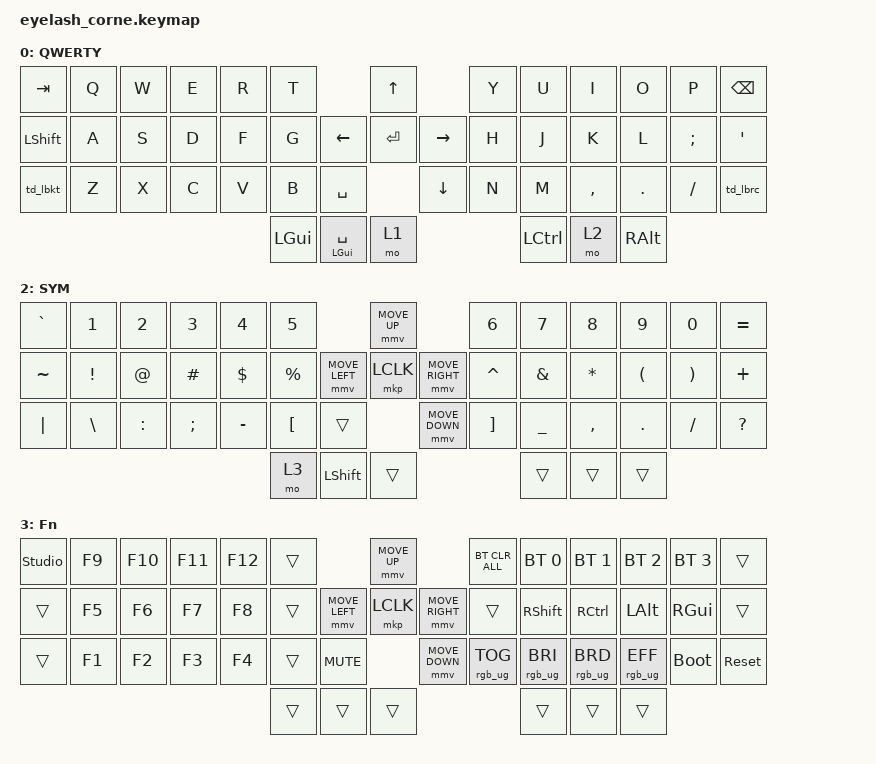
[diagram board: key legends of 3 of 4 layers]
#define ZMK_POINTING_DEFAULT_MOVE_VAL 1200  // 600
#define ZMK_POINTING_DEFAULT_SCRL_VAL 25   // 10

#include <input/processors.dtsi>
#include <zephyr/dt-bindings/input/input-event-codes.h>
#include <behaviors.dtsi>
#include <dt-bindings/zmk/bt.h>
#include <dt-bindings/zmk/keys.h>
#include <dt-bindings/zmk/outputs.h>
#include <dt-bindings/zmk/pointing.h>
#include <dt-bindings/zmk/rgb.h>

&mmv_input_listener { input-processors = <&zip_xy_scaler 2 1>; };

&msc_input_listener { input-processors = <&zip_scroll_scaler 2 1>; };

&msc {
    acceleration-exponent = <1>;
    time-to-max-speed-ms = <100>;
    delay-ms = <0>;
};

&mmv {
    time-to-max-speed-ms = <500>;
    acceleration-exponent = <1>;
    trigger-period-ms = <16>;
};

&soft_off { hold-time-ms = <2000>; };

/ {
    macros {
        lbkt_pair: lbkt_pair {
            compatible = "zmk,behavior-macro";
            #binding-cells = <0>;
            wait-ms = <0>;
            tap-ms = <10>;
            bindings = <&kp LBKT &kp RBKT &kp LEFT>;
        };

        lbrc_pair: lbrc_pair {
            compatible = "zmk,behavior-macro";
            #binding-cells = <0>;
            wait-ms = <0>;
            tap-ms = <10>;
            bindings = <&kp LBRC &kp RBRC &kp LEFT>;
        };
    };

    behaviors {
        td_lbkt: td_lbkt {
            compatible = "zmk,behavior-tap-dance";
            #binding-cells = <0>;
            tapping-term-ms = <200>;
            bindings = <&kp LBKT>, <&lbkt_pair>;
        };

        td_lbrc: td_lbrc {
            compatible = "zmk,behavior-tap-dance";
            #binding-cells = <0>;
            tapping-term-ms = <200>;
            bindings = <&kp LBRC>, <&lbrc_pair>;
        };

        gui_spc: gui_spc {
            compatible = "zmk,behavior-hold-tap";
            #binding-cells = <2>;
            flavor = "tap-preferred";
            tapping-term-ms = <200>;
            require-prior-idle-ms = <150>;
            bindings = <&kp>, <&kp>;
        };
    };

    rgb_encoder: rgb_encoder {
        compatible = "zmk,behavior-sensor-rotate";
        #sensor-binding-cells = <0>;
        bindings = <&rgb_ug RGB_BRI>, <&rgb_ug RGB_BRD>;
    };

    scroll_encoder: scroll_encoder {
        compatible = "zmk,behavior-sensor-rotate";
        #sensor-binding-cells = <0>;
        bindings = <&msc SCRL_DOWN>, <&msc SCRL_UP>;
        tap-ms = <100>;
    };

    combos {
        compatible = "zmk,combos";

        softoff {
            bindings = <&soft_off>;
            key-positions = <1 15 29>;
        };

        combo_esc {
            bindings = <&kp ESC>;
            key-positions = <24 25>;  // K + L
            timeout-ms = <100>;
        };

        combo_enter {
            bindings = <&kp ENTER>;
            key-positions = <23 24>;  // J + K
            timeout-ms = <100>;
        };
    };

    keymap {
        compatible = "zmk,keymap";

        default_layer {
            display-name = "QWERTY";
            bindings = <
&kp TAB        &kp Q    &kp W     &kp E    &kp R     &kp T                                    &kp UP                        &kp Y           &kp U           &kp I           &kp O           &kp P        &kp BSPC
&kp LSHFT      &kp A    &kp S     &kp D    &kp F     &kp G                    &kp LEFT        &kp ENTER  &kp RIGHT          &kp H           &kp J           &kp K           &kp L           &kp SEMI     &kp SQT
&td_lbkt       &kp Z    &kp X     &kp C    &kp V     &kp B      &kp SPACE                     &kp DOWN                      &kp N           &kp M           &kp COMMA       &kp DOT         &kp FSLH     &td_lbrc
                                                       &kp LGUI &gui_spc LGUI SPACE &mo 1                                               &kp LCTRL &mo 2  &kp RALT
>;
            sensor-bindings = <&inc_dec_kp C_VOLUME_UP C_VOL_DN>;
        };

        nav_layer {
            display-name = "NAV";
            bindings = <
&kp ESC        &trans   &trans    &trans    &kp LC(LS(LG(N4))) &kp LC(LA(LG(LS(T))))                                &mmv MOVE_UP                  &kp LA(LEFT)    &kp LA(DOWN)    &kp LA(UP)      &kp LA(RIGHT)   &trans       &kp LA(BSPC)
&trans         &kp LGUI &kp LALT  &kp LCTRL &kp LSHFT          &kp LC(LA(G))                        &mmv MOVE_LEFT  &mkp LCLK  &mmv MOVE_RIGHT    &kp LEFT        &kp DOWN        &kp UP          &kp RIGHT       &trans       &trans
&trans         &trans   &trans    &trans    &trans             &trans                 &kp C_MUTE                    &mmv MOVE_DOWN                &kp HOME        &kp PG_DN       &kp PG_UP       &kp END         &trans       &trans
                                                                      &trans   &trans    &trans                                              &trans&mo 3      &trans
>;
            sensor-bindings = <&scroll_encoder>;
        };

        sym_layer {
            display-name = "SYM";
            bindings = <
&kp GRAVE      &kp N1   &kp N2    &kp N3   &kp N4    &kp N5                                   &mmv MOVE_UP                  &kp N6          &kp N7          &kp N8          &kp N9          &kp N0       &kp EQUAL
&kp TILDE      &kp EXCL &kp AT    &kp HASH &kp DLLR  &kp PRCNT                &mmv MOVE_LEFT  &mkp LCLK  &mmv MOVE_RIGHT    &kp CARET       &kp AMPS        &kp ASTRK       &kp LPAR        &kp RPAR     &kp PLUS
&kp PIPE       &kp BSLH &kp COLON &kp SEMI &kp MINUS &kp LBKT   &trans                        &mmv MOVE_DOWN                &kp RBKT        &kp UNDER       &kp COMMA       &kp DOT         &kp FSLH     &kp QMARK
                                                        &mo 3    &kp LSHFT      &trans                                              &trans    &trans &trans
>;
            sensor-bindings = <&scroll_encoder>;
        };

        fn_layer {
            display-name = "Fn";
            bindings = <
&studio_unlock &kp F9   &kp F10   &kp F11  &kp F12   &trans                                   &mmv MOVE_UP                  &bt BT_CLR_ALL  &bt BT_SEL 0    &bt BT_SEL 1    &bt BT_SEL 2    &bt BT_SEL 3 &trans
&trans         &kp F5   &kp F6    &kp F7   &kp F8    &trans                   &mmv MOVE_LEFT  &mkp LCLK  &mmv MOVE_RIGHT    &trans          &kp RSHFT       &kp RCTRL       &kp LALT        &kp RGUI     &trans
&trans         &kp F1   &kp F2    &kp F3   &kp F4    &trans     &kp C_MUTE                    &mmv MOVE_DOWN                &rgb_ug RGB_TOG &rgb_ug RGB_BRI &rgb_ug RGB_BRD &rgb_ug RGB_EFF &bootloader  &sys_reset
                                                        &trans   &trans         &trans                                              &trans    &trans &trans
>;
            sensor-bindings = <&scroll_encoder>;
        };
    };
};
